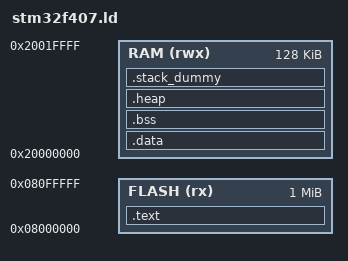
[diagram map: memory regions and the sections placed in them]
/* linker script */

MEMORY
{
  FLASH (rx)  : ORIGIN = 0x08000000, LENGTH = 1024K
  RAM   (rwx) : ORIGIN = 0x20000000, LENGTH =  128K
}

ENTRY(Reset_Handler)

SECTIONS
{
	.text :
	{
		KEEP(*(.vectors))
		*(.text*)
		*(.rodata*)
	} > FLASH


	/* Location counter can end up 2byte aligned with narrow Thumb code but
	   __etext is assumed by startup code to be the LMA of a section in RAM
	   which must be 4byte aligned */
	__etext = ALIGN (4);

	.data : AT (__etext)
	{
		__data_start__ = .;
		*(vtable)
		*(.data*)

		. = ALIGN(4);
		/* preinit data */
		PROVIDE_HIDDEN (__preinit_array_start = .);
		KEEP(*(.preinit_array))
		PROVIDE_HIDDEN (__preinit_array_end = .);

		. = ALIGN(4);
		/* init data */
		PROVIDE_HIDDEN (__init_array_start = .);
		KEEP(*(SORT(.init_array.*)))
		KEEP(*(.init_array))
		PROVIDE_HIDDEN (__init_array_end = .);

		. = ALIGN(4);
		/* finit data */
		PROVIDE_HIDDEN (__fini_array_start = .);
		KEEP(*(SORT(.fini_array.*)))
		KEEP(*(.fini_array))
		PROVIDE_HIDDEN (__fini_array_end = .);

		KEEP(*(.jcr*))
		. = ALIGN(4);
		/* All data end */
		__data_end__ = .;

	} > RAM

	.bss :
	{
		. = ALIGN(4);
		__bss_start__ = .;
		*(.bss*)
		*(COMMON)
		. = ALIGN(4);
		__bss_end__ = .;
	} > RAM

	.heap (COPY):
	{
		__end__ = .;
		PROVIDE(end = .);
		*(.heap*)
		__HeapLimit = .;
	} > RAM

	/* .stack_dummy section doesn't contain any symbols. It is only
	 * used for linker to calculate size of stack sections, and assign
	 * values to stack symbols later */
	.stack_dummy (COPY):
	{
		*(.stack*)
	} > RAM

	/* Set stack top to end of RAM, and stack limit move down by
	 * size of stack_dummy section */
	__StackTop = ORIGIN(RAM) + LENGTH(RAM);
	__StackLimit = __StackTop - SIZEOF(.stack_dummy);
	PROVIDE(__stack = __StackTop);

	/* Check if data + heap + stack exceeds RAM limit */
	ASSERT(__StackLimit >= __HeapLimit, "region RAM overflowed with stack")
}
